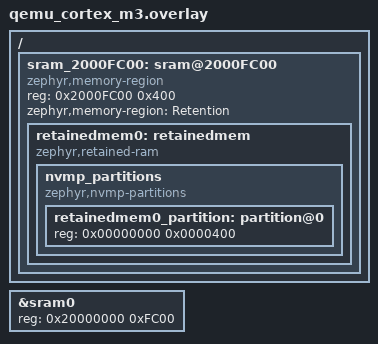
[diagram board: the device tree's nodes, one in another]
/*
 * Copyright (c) 2023 Laczen
 * SPDX-License-Identifier: Apache-2.0
 */

#include <common/mem.h>

/ {
	sram_2000FC00: sram@2000FC00 {
		compatible = "zephyr,memory-region", "mmio-sram";
		reg = <0x2000FC00 0x400>;
                zephyr,memory-region = "Retention";
                status = "okay";

		retainedmem0: retainedmem {
			compatible = "zephyr,retained-ram", "zephyr,nvmp-retained-mem";
			status = "okay";
			nvmp_partitions {
				compatible = "zephyr,nvmp-partitions";
				#address-cells = <1>;
				#size-cells = <1>;

				retainedmem0_partition: partition@0 {
					reg = <0x00000000 0x0000400>;
				};

			};
	        };
        };
};

&sram0 {
	reg = <0x20000000 0xFC00>;
};
